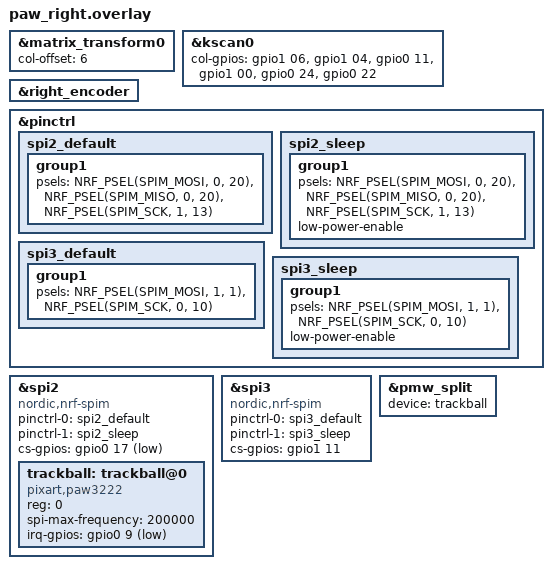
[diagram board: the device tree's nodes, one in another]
/*
 * Copyright (c) 2020 ZMK Contributors
 *
 * SPDX-License-Identifier: MIT
 */
 
#include "paw.dtsi"

&matrix_transform0 {
	col-offset = <6>;
};

&kscan0 {
	col-gpios
		= <&gpio1 06 (GPIO_ACTIVE_HIGH | GPIO_PULL_DOWN)>
		, <&gpio1 04 (GPIO_ACTIVE_HIGH | GPIO_PULL_DOWN)>
		, <&gpio0 11 (GPIO_ACTIVE_HIGH | GPIO_PULL_DOWN)>
		, <&gpio1 00 (GPIO_ACTIVE_HIGH | GPIO_PULL_DOWN)>
		, <&gpio0 24 (GPIO_ACTIVE_HIGH | GPIO_PULL_DOWN)>
		, <&gpio0 22 (GPIO_ACTIVE_HIGH | GPIO_PULL_DOWN)>
		;
};

&right_encoder {
    status = "okay";
};

&pinctrl {
    spi2_default: spi2_default {
				group1 {
						psels = <NRF_PSEL(SPIM_MOSI, 0, 20)>,
						<NRF_PSEL(SPIM_MISO, 0, 20)>,
						<NRF_PSEL(SPIM_SCK, 1, 13)>;
				};
		};
	
    spi2_sleep: spi2_sleep {
				group1 {
						psels = <NRF_PSEL(SPIM_MOSI, 0, 20)>,
						<NRF_PSEL(SPIM_MISO, 0, 20)>,
						<NRF_PSEL(SPIM_SCK, 1, 13)>;
						low-power-enable;
				};
		};
    spi3_default: spi3_default {
				group1 {
						psels = <NRF_PSEL(SPIM_MOSI, 1, 1)>,
						<NRF_PSEL(SPIM_SCK, 0, 10)>;
				};
		};
	
    spi3_sleep: spi3_sleep {
				group1 {
						psels = <NRF_PSEL(SPIM_MOSI, 1, 1)>,
						<NRF_PSEL(SPIM_SCK, 0, 10)>;
						low-power-enable;
				};
		};
};

&spi2 {
		 status ="okay";
    compatible = "nordic,nrf-spim";
    pinctrl-0 = <&spi2_default>;
    pinctrl-1 = <&spi2_sleep>;
    pinctrl-names = "default", "sleep";
    cs-gpios = <&gpio0 17 GPIO_ACTIVE_LOW>;
		trackball: trackball@0 {
			status = "okay";
			compatible ="pixart,paw3222";
			reg = <0>;
			spi-max-frequency = <200000>;
			irq-gpios = <&gpio0 9 GPIO_ACTIVE_LOW>;
	};
};

nice_view_spi: &spi3 {
    compatible = "nordic,nrf-spim";
    pinctrl-0 = <&spi3_default>;
    pinctrl-1 = <&spi3_sleep>;
    pinctrl-names = "default", "sleep";
    cs-gpios = <&gpio1 11 (GPIO_ACTIVE_HIGH | GPIO_PULL_DOWN) >;
};

lpm_view_spi: &spi3 {
    compatible = "nordic,nrf-spim";
    pinctrl-0 = <&spi3_default>;
    pinctrl-1 = <&spi3_sleep>;
    pinctrl-names = "default", "sleep";
    cs-gpios = <&gpio1 11 (GPIO_ACTIVE_HIGH | GPIO_PULL_DOWN)>;
};

&pmw_split {
	device = <&trackball>;
// see https://zmk.dev/docs/keymaps/input-processors for more information
	// input-processors = <&zip_xy_transform (INPUT_TRANSFORM_XY_SWAP | INPUT_TRANSFORM_X_INVERT)>;
};
